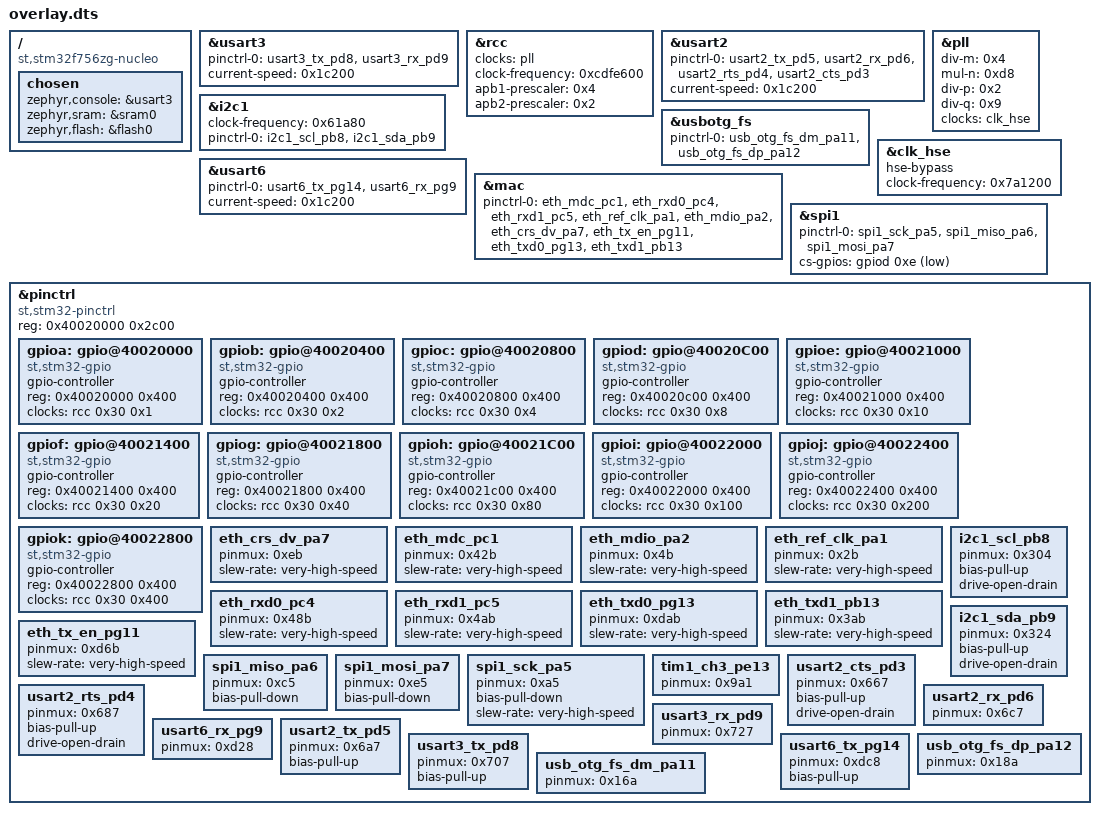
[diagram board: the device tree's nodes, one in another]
/ {
	compatible = "st,stm32f756zg-nucleo";
	chosen {
		zephyr,console = &usart3;
		zephyr,sram = &sram0;
		zephyr,flash = &flash0;
	};
};
&usart3{
	status = "okay";
	pinctrl-0 = < &usart3_tx_pd8 &usart3_rx_pd9 >;
	pinctrl-names = "default";
	current-speed = < 0x1c200 >;
};
&rcc{
	clocks = < &pll >;
	clock-frequency = < 0xcdfe600 >;
	apb1-prescaler = < 0x4 >;
	apb2-prescaler = < 0x2 >;
};
&usart2{
	status = "okay";
	pinctrl-0 = < &usart2_tx_pd5 &usart2_rx_pd6 &usart2_rts_pd4 &usart2_cts_pd3 >;
	pinctrl-names = "default";
	current-speed = < 0x1c200 >;
};
&i2c1{
	clock-frequency = < 0x61a80 >;
	status = "okay";
	pinctrl-0 = < &i2c1_scl_pb8 &i2c1_sda_pb9 >;
	pinctrl-names = "default";
};
&usbotg_fs{
	status = "okay";
	pinctrl-0 = < &usb_otg_fs_dm_pa11 &usb_otg_fs_dp_pa12 >;
	pinctrl-names = "default";
};
&pll{
	status = "okay";
	div-m = < 0x4 >;
	mul-n = < 0xd8 >;
	div-p = < 0x2 >;
	div-q = < 0x9 >;
	clocks = < &clk_hse >;
};
&usart6{
	status = "okay";
	pinctrl-0 = < &usart6_tx_pg14 &usart6_rx_pg9 >;
	pinctrl-names = "default";
	current-speed = < 0x1c200 >;
};
&clk_hse{
	status = "okay";
	hse-bypass;
	clock-frequency = < 0x7a1200 >;
};
&mac{
	status = "okay";
	pinctrl-0 = < &eth_mdc_pc1 &eth_rxd0_pc4 &eth_rxd1_pc5 &eth_ref_clk_pa1 &eth_mdio_pa2 &eth_crs_dv_pa7 &eth_tx_en_pg11 &eth_txd0_pg13 &eth_txd1_pb13 >;
	pinctrl-names = "default";
};
&spi1{
	status = "okay";
	pinctrl-0 = < &spi1_sck_pa5 &spi1_miso_pa6 &spi1_mosi_pa7 >;
	pinctrl-names = "default";
	cs-gpios = < &gpiod 0xe 0x11 >;
};
&pinctrl{
	compatible = "st,stm32-pinctrl";
	#address-cells = < 0x1 >;
	#size-cells = < 0x1 >;
	reg = < 0x40020000 0x2c00 >;
	gpioa: gpio@40020000 {
		compatible = "st,stm32-gpio";
		gpio-controller;
		#gpio-cells = < 0x2 >;
		reg = < 0x40020000 0x400 >;
		clocks = < &rcc 0x30 0x1 >;
	};
	gpiob: gpio@40020400 {
		compatible = "st,stm32-gpio";
		gpio-controller;
		#gpio-cells = < 0x2 >;
		reg = < 0x40020400 0x400 >;
		clocks = < &rcc 0x30 0x2 >;
	};
	gpioc: gpio@40020800 {
		compatible = "st,stm32-gpio";
		gpio-controller;
		#gpio-cells = < 0x2 >;
		reg = < 0x40020800 0x400 >;
		clocks = < &rcc 0x30 0x4 >;
	};
	gpiod: gpio@40020C00 {
		compatible = "st,stm32-gpio";
		gpio-controller;
		#gpio-cells = < 0x2 >;
		reg = < 0x40020c00 0x400 >;
		clocks = < &rcc 0x30 0x8 >;
	};
	gpioe: gpio@40021000 {
		compatible = "st,stm32-gpio";
		gpio-controller;
		#gpio-cells = < 0x2 >;
		reg = < 0x40021000 0x400 >;
		clocks = < &rcc 0x30 0x10 >;
	};
	gpiof: gpio@40021400 {
		compatible = "st,stm32-gpio";
		gpio-controller;
		#gpio-cells = < 0x2 >;
		reg = < 0x40021400 0x400 >;
		clocks = < &rcc 0x30 0x20 >;
	};
	gpiog: gpio@40021800 {
		compatible = "st,stm32-gpio";
		gpio-controller;
		#gpio-cells = < 0x2 >;
		reg = < 0x40021800 0x400 >;
		clocks = < &rcc 0x30 0x40 >;
	};
	gpioh: gpio@40021C00 {
		compatible = "st,stm32-gpio";
		gpio-controller;
		#gpio-cells = < 0x2 >;
		reg = < 0x40021c00 0x400 >;
		clocks = < &rcc 0x30 0x80 >;
	};
	gpioi: gpio@40022000 {
		compatible = "st,stm32-gpio";
		gpio-controller;
		#gpio-cells = < 0x2 >;
		reg = < 0x40022000 0x400 >;
		clocks = < &rcc 0x30 0x100 >;
	};
	gpioj: gpio@40022400 {
		compatible = "st,stm32-gpio";
		gpio-controller;
		#gpio-cells = < 0x2 >;
		reg = < 0x40022400 0x400 >;
		clocks = < &rcc 0x30 0x200 >;
	};
	gpiok: gpio@40022800 {
		compatible = "st,stm32-gpio";
		gpio-controller;
		#gpio-cells = < 0x2 >;
		reg = < 0x40022800 0x400 >;
		clocks = < &rcc 0x30 0x400 >;
	};
	eth_crs_dv_pa7: eth_crs_dv_pa7 {
		pinmux = < 0xeb >;
		slew-rate = "very-high-speed";
	};
	eth_mdc_pc1: eth_mdc_pc1 {
		pinmux = < 0x42b >;
		slew-rate = "very-high-speed";
	};
	eth_mdio_pa2: eth_mdio_pa2 {
		pinmux = < 0x4b >;
		slew-rate = "very-high-speed";
	};
	eth_ref_clk_pa1: eth_ref_clk_pa1 {
		pinmux = < 0x2b >;
		slew-rate = "very-high-speed";
	};
	eth_rxd0_pc4: eth_rxd0_pc4 {
		pinmux = < 0x48b >;
		slew-rate = "very-high-speed";
	};
	eth_rxd1_pc5: eth_rxd1_pc5 {
		pinmux = < 0x4ab >;
		slew-rate = "very-high-speed";
	};
	eth_txd0_pg13: eth_txd0_pg13 {
		pinmux = < 0xdab >;
		slew-rate = "very-high-speed";
	};
	eth_txd1_pb13: eth_txd1_pb13 {
		pinmux = < 0x3ab >;
		slew-rate = "very-high-speed";
	};
	eth_tx_en_pg11: eth_tx_en_pg11 {
		pinmux = < 0xd6b >;
		slew-rate = "very-high-speed";
	};
	i2c1_scl_pb8: i2c1_scl_pb8 {
		pinmux = < 0x304 >;
		bias-pull-up;
		drive-open-drain;
	};
	i2c1_sda_pb9: i2c1_sda_pb9 {
		pinmux = < 0x324 >;
		bias-pull-up;
		drive-open-drain;
	};
	spi1_miso_pa6: spi1_miso_pa6 {
		pinmux = < 0xc5 >;
		bias-pull-down;
	};
	spi1_mosi_pa7: spi1_mosi_pa7 {
		pinmux = < 0xe5 >;
		bias-pull-down;
	};
	spi1_sck_pa5: spi1_sck_pa5 {
		pinmux = < 0xa5 >;
		bias-pull-down;
		slew-rate = "very-high-speed";
	};
	tim1_ch3_pe13: tim1_ch3_pe13 {
		pinmux = < 0x9a1 >;
	};
	usart2_cts_pd3: usart2_cts_pd3 {
		pinmux = < 0x667 >;
		bias-pull-up;
		drive-open-drain;
	};
	usart2_rts_pd4: usart2_rts_pd4 {
		pinmux = < 0x687 >;
		bias-pull-up;
		drive-open-drain;
	};
	usart2_rx_pd6: usart2_rx_pd6 {
		pinmux = < 0x6c7 >;
	};
	usart3_rx_pd9: usart3_rx_pd9 {
		pinmux = < 0x727 >;
	};
	usart6_rx_pg9: usart6_rx_pg9 {
		pinmux = < 0xd28 >;
	};
	usart2_tx_pd5: usart2_tx_pd5 {
		pinmux = < 0x6a7 >;
		bias-pull-up;
	};
	usart3_tx_pd8: usart3_tx_pd8 {
		pinmux = < 0x707 >;
		bias-pull-up;
	};
	usart6_tx_pg14: usart6_tx_pg14 {
		pinmux = < 0xdc8 >;
		bias-pull-up;
	};
	usb_otg_fs_dm_pa11: usb_otg_fs_dm_pa11 {
		pinmux = < 0x16a >;
	};
	usb_otg_fs_dp_pa12: usb_otg_fs_dp_pa12 {
		pinmux = < 0x18a >;
	};
};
